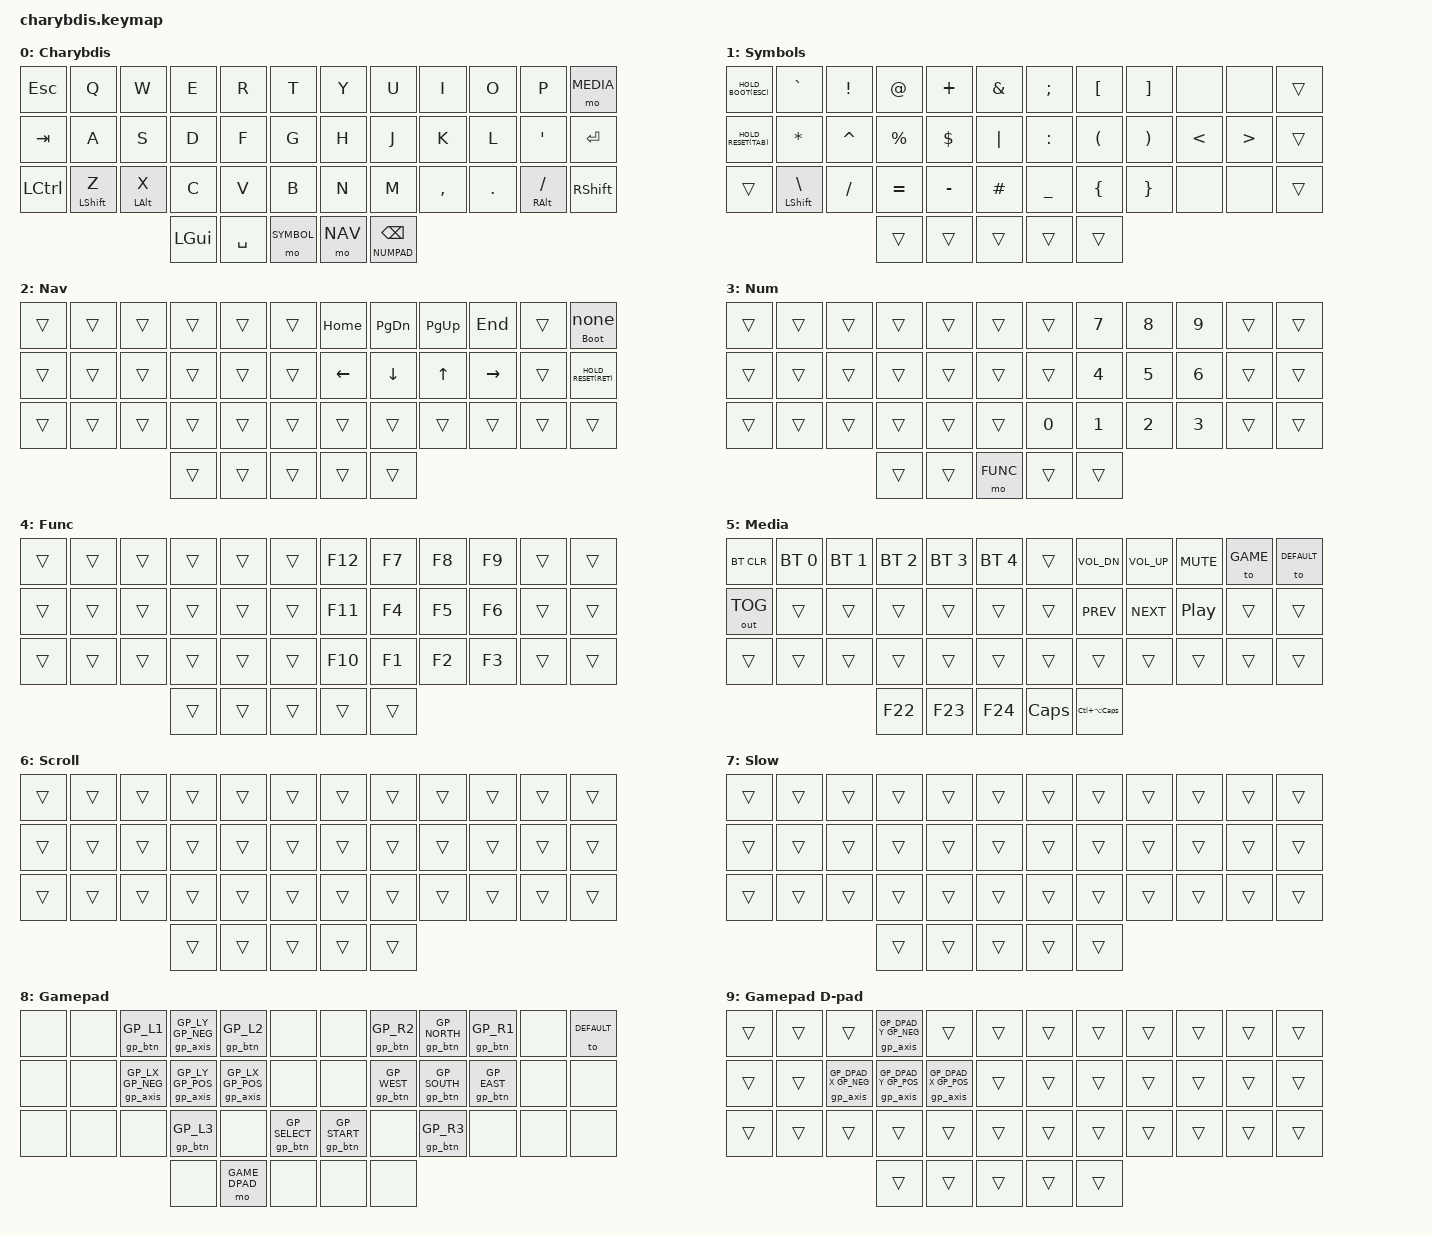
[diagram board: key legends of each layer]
/*
 * Copyright (c) 2020 The ZMK Contributors
 *
 * SPDX-License-Identifier: MIT
 */

#include <behaviors.dtsi>
#include <behaviors/hid_io_gamepad.dtsi>
#include <dt-bindings/zmk/hid-io/gamepad.h>
#include <dt-bindings/zmk/keys.h>
#include <dt-bindings/zmk/bt.h>
#include <dt-bindings/zmk/ext_power.h>
#include <dt-bindings/zmk/behaviors.h>
#include <dt-bindings/zmk/outputs.h>
#include <dt-bindings/zmk/pointing.h>

#define DEFAULT 0
#define SYMBOL  1
#define NAV     2
#define NUMPAD  3
#define FUNC    4
#define MEDIA   5
#define SCROLL  6
#define SLOW    7
#define GAME    8
#define GAME_DPAD 9

#define HOLD_BOOT(key) &btldr_hold &trans key
#define HOLD_RESET(key) &reset_hold &trans key
#define HOLD_BOOT_NONE &btldr_hold_none 0 0

#define PAD_A          &gp_btn GP_SOUTH
#define PAD_B          &gp_btn GP_EAST
#define PAD_X          &gp_btn GP_WEST
#define PAD_Y          &gp_btn GP_NORTH
#define PAD_LB         &gp_btn GP_L1
#define PAD_RB         &gp_btn GP_R1
#define PAD_LT         &gp_btn GP_L2
#define PAD_RT         &gp_btn GP_R2
#define PAD_SELECT     &gp_btn GP_SELECT
#define PAD_START      &gp_btn GP_START
#define PAD_L3         &gp_btn GP_L3
#define PAD_R3         &gp_btn GP_R3
#define PAD_LS_LEFT    &gp_axis GP_LX GP_NEG
#define PAD_LS_RIGHT   &gp_axis GP_LX GP_POS
#define PAD_LS_UP      &gp_axis GP_LY GP_NEG
#define PAD_LS_DOWN    &gp_axis GP_LY GP_POS
#define PAD_DPAD_LEFT  &gp_axis GP_DPAD_X GP_NEG
#define PAD_DPAD_RIGHT &gp_axis GP_DPAD_X GP_POS
#define PAD_DPAD_UP    &gp_axis GP_DPAD_Y GP_NEG
#define PAD_DPAD_DOWN  &gp_axis GP_DPAD_Y GP_POS

/ {
        behaviors {
                btldr_hold: btldr_hold {
                        compatible = "zmk,behavior-hold-tap";
                        #binding-cells = <2>;
                        tapping-term-ms = <5000>;
                        flavor = "tap-preferred";
                        display-name = "Bootloader Hold";
                        bindings = <&bootloader>, <&kp>;
                };
                btldr_hold_none: btldr_hold_none {
                        compatible = "zmk,behavior-hold-tap";
                        #binding-cells = <2>;
                        tapping-term-ms = <5000>;
                        flavor = "tap-preferred";
                        display-name = "Bootloader Hold (no tap)";
                        bindings = <&bootloader>, <&none>;
                };
                reset_hold: reset_hold {
                        compatible = "zmk,behavior-hold-tap";
                        #binding-cells = <2>;
                        tapping-term-ms = <5000>;
                        flavor = "tap-preferred";
                        display-name = "Reset Hold";
                        bindings = <&sys_reset>, <&kp>;
                };
                lt_backspace: layer_tap_backspace {
                        compatible = "zmk,behavior-hold-tap";
                        #binding-cells = <2>;
                        flavor = "hold-preferred";
                        tapping-term-ms = <200>;
                        quick-tap-ms = <500>;
                        bindings = <&mo>, <&kp>;
                        display-name = "Layer-Tap";
                };
        };
        combos {
                compatible = "zmk,combos";
                dongle_bootloader_left {
                        timeout-ms = <50>;
                        key-positions = <15 16 17>;
                        bindings = <&bootloader>;
                        layers = <SYMBOL>;
                };
                dongle_reset_left {
                        timeout-ms = <50>;
                        key-positions = <27 28 29>;
                        bindings = <&sys_reset>;
                        layers = <SYMBOL>;
                };
                dongle_bootloader_right {
                        timeout-ms = <50>;
                        key-positions = <18 19 20>;
                        bindings = <&bootloader>;
                        layers = <NAV>;
                };
                dongle_reset_right {
                        timeout-ms = <50>;
                        key-positions = <30 31 32>;
                        bindings = <&sys_reset>;
                        layers = <NAV>;
                };

                /*
                * right half
                */
                combo_left_click_r {
                        bindings = <&mkp LCLK>;
                        key-positions = <31 32>;
                        layers = <DEFAULT>, <SCROLL>, <SLOW>;
                };
                combo_middle_click_r {
                        bindings = <&mkp MCLK>;
                        key-positions = <31 32 33>;
                        layers = <DEFAULT>, <SCROLL>, <SLOW>;
                };
                combo_right_click_r {
                        bindings = <&mkp RCLK>;
                        key-positions = <32 33>;
                        layers = <DEFAULT>, <SCROLL>, <SLOW>;
                };
                combo_scroll_r {
                        bindings = <&mo SCROLL>;
                        key-positions = <31 33>;
                        layers = <DEFAULT>, <SCROLL>, <SLOW>;
                };
                combo_mb4_r {
                        bindings = <&mkp MB4>;
                        key-positions = <31 39>;
                        layers = <DEFAULT>, <SCROLL>, <SLOW>;
                };
                combo_mb5_r {
                        bindings = <&mkp MB5>;
                        key-positions = <31 40>;
                        layers = <DEFAULT>, <SCROLL>, <SLOW>;
                };

                /*
                * left half
                */
                combo_left_click_l {
                        bindings = <&mkp LCLK>;
                        key-positions = <27 28>;
                        layers = <DEFAULT>, <SCROLL>, <SLOW>;
                };
                combo_middle_click_l {
                        bindings = <&mkp MCLK>;
                        key-positions = <26 27 28>;
                        layers = <DEFAULT>, <SCROLL>, <SLOW>;
                };
                combo_right_click_l {
                        bindings = <&mkp RCLK>;
                        key-positions = <26 27>;
                        layers = <DEFAULT>, <SCROLL>, <SLOW>;
                };
                combo_scroll_l {
                        bindings = <&mo SCROLL>;
                        key-positions = <26 28>;
                        layers = <DEFAULT>, <SCROLL>, <SLOW>;
                };
                combo_mb4_l {
                        bindings = <&mkp MB4>;
                        key-positions = <28 36>;
                        layers = <DEFAULT>, <SCROLL>, <SLOW>;
                };
                combo_mb5_l {
                        bindings = <&mkp MB5>;
                        key-positions = <28 37>;
                        layers = <DEFAULT>, <SCROLL>, <SLOW>;
                };
        };

        keymap {
                compatible = "zmk,keymap";

                default_layer {
                        display-name = "Charybdis";
                        bindings = <
   &kp ESC   &kp Q        &kp W         &kp E     &kp R      &kp T               &kp Y     &kp U      &kp I     &kp O     &kp P           &mo MEDIA
   &kp TAB   &kp A        &kp S         &kp D     &kp F      &kp G               &kp H     &kp J      &kp K     &kp L     &kp SQT         &kp RET
   &kp LCTRL &mt LSHFT Z  &mt LALT X    &kp C     &kp V      &kp B               &kp N     &kp M      &kp COMMA &kp DOT   &mt RALT FSLH   &kp RSHFT
                                        &kp LGUI  &kp SPACE  &mo SYMBOL          &mo NAV   &lt_backspace NUMPAD BSPC
                        >;
                };

                symbol_layer {
                        display-name = "Symbols";
                        bindings = <
   HOLD_BOOT(ESC)  &kp GRAVE        &kp EXCL  &kp AT    &kp PLUS  &kp AMPS        &kp SEMI  &kp LBKT  &kp RBKT  &none    &none    &trans
   HOLD_RESET(TAB) &kp ASTRK        &kp CARET &kp PRCNT &kp DLLR  &kp PIPE        &kp COLON &kp LPAR  &kp RPAR  &kp LT   &kp GT   &trans
   &trans          &mt LSHFT BSLH   &kp SLASH &kp EQUAL &kp MINUS &kp HASH        &kp UNDER &kp LBRC  &kp RBRC  &none    &none    &trans
                                             &trans    &trans    &trans          &trans   &trans
                        >;
                };

                navigation_layer {
                        display-name = "Nav";
                        bindings = <
   &trans    &trans    &trans    &trans   &trans   &trans       &kp HOME     &kp PG_DN &kp PG_UP &kp END    &trans   HOLD_BOOT_NONE
   &trans    &trans    &trans    &trans   &trans   &trans       &kp LEFT     &kp DOWN  &kp UP    &kp RIGHT  &trans   HOLD_RESET(RET)
   &trans    &trans    &trans    &trans   &trans   &trans       &trans       &trans    &trans    &trans     &trans   &trans
                                 &trans   &trans   &trans       &trans       &trans
                        >;
                };

                numpad_layer {
                        display-name = "Num";
                        bindings = <
   &trans  &trans  &trans  &trans  &trans  &trans           &trans      &kp N7  &kp N8  &kp N9  &trans    &trans
   &trans  &trans  &trans  &trans  &trans  &trans           &trans      &kp N4  &kp N5  &kp N6  &trans    &trans
   &trans  &trans  &trans  &trans  &trans  &trans           &kp N0      &kp N1  &kp N2  &kp N3  &trans    &trans
                           &trans  &trans  &mo FUNC         &trans      &trans
                        >;
                };

                function_layer {
                        display-name = "Func";
                        bindings = <
   &trans  &trans  &trans  &trans  &trans  &trans           &kp F12     &kp F7  &kp F8  &kp F9  &trans    &trans
   &trans  &trans  &trans  &trans  &trans  &trans           &kp F11     &kp F4  &kp F5  &kp F6  &trans    &trans
   &trans  &trans  &trans  &trans  &trans  &trans           &kp F10     &kp F1  &kp F2  &kp F3  &trans    &trans
                           &trans  &trans  &trans           &trans      &trans
                        >;
                };

                media_layer {
                        display-name = "Media";
                        bindings = <
   &bt BT_CLR       &bt BT_SEL 0 &bt BT_SEL 1 &bt BT_SEL 2 &bt BT_SEL 3 &bt BT_SEL 4     &trans   &kp C_VOL_DN  &kp C_VOL_UP  &kp C_MUTE        &to GAME   &to DEFAULT
   &out OUT_TOG     &trans       &trans       &trans       &trans       &trans           &trans   &kp C_PREV    &kp C_NEXT    &kp C_PLAY_PAUSE  &trans     &trans
   &trans           &trans       &trans       &trans       &trans       &trans           &trans   &trans        &trans        &trans            &trans     &trans
                                              &kp F22      &kp F23      &kp F24          &kp CAPS       &kp LC(LA(CAPS))
                        >;
                };

                scroll_layer {
                        display-name = "Scroll";
                        bindings = <
   &trans    &trans    &trans    &trans    &trans    &trans        &trans      &trans    &trans    &trans    &trans    &trans
   &trans    &trans    &trans    &trans    &trans    &trans        &trans      &trans    &trans    &trans    &trans    &trans
   &trans    &trans    &trans    &trans    &trans    &trans        &trans      &trans    &trans    &trans    &trans    &trans
                                 &trans    &trans    &trans        &trans      &trans
                        >;
                };

                slow_layer {
                        display-name = "Slow";
                        bindings = <
   &trans    &trans    &trans    &trans    &trans    &trans        &trans       &trans    &trans    &trans    &trans    &trans
   &trans    &trans    &trans    &trans    &trans    &trans        &trans       &trans    &trans    &trans    &trans    &trans
   &trans    &trans    &trans    &trans    &trans    &trans        &trans       &trans    &trans    &trans    &trans    &trans
                                 &trans    &trans    &trans        &trans       &trans
                        >;
                };

                game_layer {
                        display-name = "Gamepad";
                        bindings = <
   &none  &none  PAD_LB       PAD_LS_UP    PAD_LT        &none                 &none        PAD_RT     PAD_Y    PAD_RB  &none    &to DEFAULT
   &none  &none  PAD_LS_LEFT  PAD_LS_DOWN  PAD_LS_RIGHT  &none                 &none        PAD_X      PAD_A    PAD_B   &none    &none
   &none  &none  &none        PAD_L3       &none         PAD_SELECT            PAD_START    &none      PAD_R3   &none   &none    &none
                          &none  &mo GAME_DPAD  &none                          &none  &none
                        >;
                };

                game_dpad_layer {
                        display-name = "Gamepad D-pad";
                        bindings = <
   &trans  &trans  &trans         PAD_DPAD_UP    &trans          &trans              &trans  &trans  &trans  &trans  &trans  &trans
   &trans  &trans  PAD_DPAD_LEFT  PAD_DPAD_DOWN  PAD_DPAD_RIGHT  &trans              &trans  &trans  &trans  &trans  &trans  &trans
   &trans  &trans  &trans         &trans         &trans          &trans              &trans  &trans  &trans  &trans  &trans  &trans
                                                 &trans  &trans  &trans              &trans  &trans
                        >;
                };

        };
};
